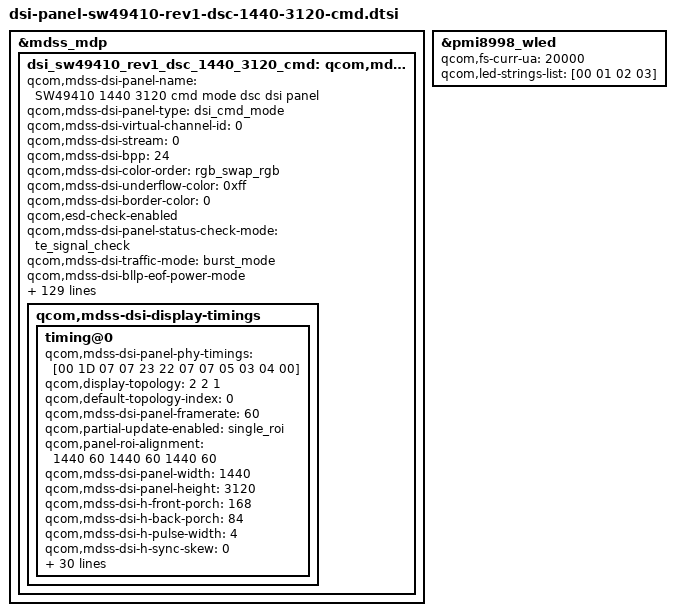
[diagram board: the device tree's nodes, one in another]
/* Copyright (c) 2014, Code Aurora Forum. All rights reserved.
 *
 * This program is free software; you can redistribute it and/or modify
 * it under the terms of the GNU General Public License version 2 and
 * only version 2 as published by the Free Software Foundation.
 *
 * This program is distributed in the hope that it will be useful,
 * but WITHOUT ANY WARRANTY; without even the implied warranty of
 * MERCHANTABILITY or FITNESS FOR A PARTICULAR PURPOSE.  See the
 * GNU General Public License for more details.
 */

&mdss_mdp {
	dsi_sw49410_rev1_dsc_1440_3120_cmd: qcom,mdss_dsi_sw49410_rev1_dsc_1440_3120_cmd {
		qcom,mdss-dsi-panel-name = "SW49410 1440 3120 cmd mode dsc dsi panel";
		qcom,mdss-dsi-panel-type = "dsi_cmd_mode";
		qcom,mdss-dsi-virtual-channel-id = <0>;
		qcom,mdss-dsi-stream = <0>;
		qcom,mdss-dsi-bpp = <24>;
		qcom,mdss-dsi-color-order = "rgb_swap_rgb";
		qcom,mdss-dsi-underflow-color = <0xff>;
		qcom,mdss-dsi-border-color = <0>;
		qcom,esd-check-enabled;
		qcom,mdss-dsi-panel-status-check-mode = "te_signal_check";
		qcom,mdss-dsi-traffic-mode = "burst_mode";
		qcom,mdss-dsi-bllp-eof-power-mode;
		qcom,mdss-dsi-bllp-power-mode;
		qcom,mdss-dsi-lane-0-state;
		qcom,mdss-dsi-lane-1-state;
		qcom,mdss-dsi-lane-2-state;
		qcom,mdss-dsi-lane-3-state;
		qcom,mdss-dsi-reset-sequence = <1 10>, <0 10>, <1 10>;
		qcom,mdss-dsi-bl-max-level = <4095>;
		qcom,adjust-timer-wakeup-ms = <1>;
		qcom,mdss-dsi-dma-trigger = "trigger_sw";
		qcom,mdss-dsi-mdp-trigger = "none";
		qcom,mdss-dsi-te-pin-select = <1>;
		qcom,mdss-dsi-wr-mem-start = <0x2c>;
		qcom,mdss-dsi-wr-mem-continue = <0x3c>;
		qcom,mdss-dsi-te-dcs-command = <1>;
		qcom,mdss-dsi-te-check-enable;
		qcom,mdss-dsi-te-using-te-pin;
		qcom,ulps-enabled;
		qcom,suspend-ulps-enabled;
		qcom,mdss-dsi-lp11-init;
		qcom,mdss-dsi-tx-eot-append;
		qcom,mdss-mdp-transfer-time-us = <15200>;

		lge,use-mplus;
		lge,use-hl-mode;
		lge,use-u2-fsc;
		lge,fsc-curr-ua-u3 = <20000>;
		lge,fsc-curr-ua-u2 = <2500>;
		lge,incell-panel;
		lge,use-color-manager;
		lge,drs-mngr-enabled;
		lge,use-ambient;
		lge,aod-interface-data = <0x144>; /* QHD = 1, FHD = 4, HD = 4 */
		lge,use-panel-reset-low-before-lp11;
		lge,use-extra-recovery-cmd;

		qcom,mdss-dsi-panel-hdr-enabled;
		qcom,mdss-dsi-panel-hdr-color-primaries = <14649 15851 33084 15473 13806 31961 7476 2719>;
		qcom,mdss-dsi-panel-peak-brightness = <5000000>;	/* max. 500nits */
		qcom,mdss-dsi-panel-blackness-level = <3022>;

		lge,blmap = <
			0
			16 16 16 16 16 16 16 16 16 16 16 16 16 16 17 17 17 17 18 18
			18 18 19 20 21 22 23 24 25 26 27 28 29 30 31 32 34 35 37 38
			40 42 43 45 46 48 49 51 53 56 59 63 66 70 73 76 80 83 87 90
			93 96 99 103 106 109 112 115 119 122 125 128 132 136 141 146 151 155 160 165
			170 174 179 184 189 194 199 205 210 215 221 226 232 237 242 248 253 259 266 274
			281 289 296 304 311 319 326 334 342 349 356 363 370 378 385 392 399 407 414 421
			428 436 445 454 464 473 482 492 501 510 520 529 538 548 558 569 580 591 602 612
			623 634 645 655 667 677 687 697 707 717 727 738 748 758 768 778 788 799 811 823
			835 847 859 872 880 896 908 920 932 945 957 969 981 994 1006 1018 1031 1043 1055 1068
			1080 1092 1105 1119 1134 1149 1164 1178 1193 1208 1223 1237 1252 1267 1282 1296 1311 1326 1341 1356
			1371 1385 1400 1415 1430 1445 1460 1475 1493 1512 1530 1549 1568 1586 1605 1624 1642 1661 1680 1697
			1714 1732 1749 1766 1784 1801 1819 1836 1853 1871 1888 1906 1926 1946 1966 1986 2006 2026 2046 2066
			2086 2106 2126 2147 2170 2194 2218 2242 2266 2290 2314 2338 2362 2386 2410
		>;

		lge,blmap-psm = <
			0
			16 16 16 16 16 16 16 16 16 16 16 16 16 17 17 17 17 17 17 18
			18 18 18 19 20 21 21 22 23 24 25 26 26 27 28 29 31 32 33 35
			36 37 38 40 41 42 44 45 47 49 52 54 56 58 60 62 65 67 69 71
			74 77 80 82 85 88 91 94 97 99 102 105 109 113 116 120 124 128 131 135
			139 143 146 150 154 158 163 167 171 175 180 184 188 192 197 201 205 210 216 221
			227 232 238 243 248 254 259 265 270 276 283 289 295 301 308 314 320 326 333 339
			345 352 359 366 373 380 388 395 402 409 416 423 430 437 444 451 459 466 473 480
			487 494 502 509 516 523 532 540 549 558 566 575 584 592 601 610 618 627 636 646
			655 665 674 684 693 702 712 721 731 740 751 761 772 782 793 804 814 825 835 846
			856 867 878 888 899 909 920 931 941 952 963 973 984 994 1005 1018 1030 1043 1055 1068
			1080 1093 1105 1118 1130 1143 1155 1168 1182 1195 1209 1222 1236 1249 1262 1276 1289 1303 1316 1331
			1345 1360 1374 1389 1404 1418 1433 1447 1462 1476 1491 1506 1520 1535 1549 1564 1578 1593 1607 1622
			1636 1651 1665 1680 1699 1717 1736 1755 1773 1792 1810 1829 1848 1866 1885
		>;

		lge,blmap-gal = <
			0
			16 16 16 16 16 16 16 16 16 16 16 17 17 17 18 18 18 18 19 19
			19 20 20 21 22 23 24 25 26 27 28 29 30 31 32 34 36 38 40 42
			44 45 47 49 51 53 55 57 60 63 66 69 72 75 78 81 84 87 90 93
			97 101 105 109 113 118 122 126 130 134 138 142 147 152 157 162 167 173 178 183
			188 193 198 203 209 215 221 227 233 239 244 250 256 262 268 274 280 287 295 302
			309 317 324 331 339 346 353 361 368 377 386 394 403 412 421 429 438 447 456 464
			473 482 492 501 511 520 530 539 548 558 567 577 586 596 606 616 626 636 646 655
			665 675 685 695 705 715 727 739 751 763 775 788 800 812 824 836 848 860 873 887
			900 913 926 940 953 966 979 993 1006 1019 1034 1048 1063 1077 1092 1107 1121 1136 1150 1165
			1179 1194 1209 1223 1238 1253 1267 1282 1297 1312 1326 1341 1356 1370 1385 1403 1420 1438 1456 1473
			1491 1509 1526 1544 1562 1579 1597 1616 1635 1654 1673 1692 1711 1730 1749 1768 1787 1806 1825 1846
			1866 1887 1908 1928 1949 1970 1990 2011 2032 2052 2073 2093 2114 2134 2155 2175 2195 2216 2236 2256
			2277 2297 2318 2338 2365 2391 2418 2444 2471 2497 2524 2550 2577 2603 2630
		>;

		lge,blmap-hqc = <
			0
			16 16 16 16 16 16 16 16 16 16 16 16 17 17 17 17 18 18 18 18
			19 19 19 20 21 22 23 24 26 27 28 29 30 31 32 34 36 37 39 41
			43 44 46 48 50 51 53 55 58 61 64 67 70 73 75 78 81 84 87 90
			94 98 102 106 110 114 118 122 126 130 134 138 143 148 152 157 162 167 171
			176 181 186 190 195 201 207 212 218 224 230 235 241 247 253 258 264 270 277 284
			291 298 305 313 320 327 334 341 348 355 363 371 380 388 396 404 412 420 429 437
			445 453 462 472 481 490 500 509 518 528 537 546 556 565 575 584 594 603 613 623
			632 642 652 661 671 680 690 702 714 726 738 750 762 773 785 797 809 821 833 846
			859 872 885 898 912 925 938 951 964 977 990 1005 1020 1035 1050 1065 1080 1095 1110 1125
			1140 1155 1170 1185 1199 1214 1228 1243 1258 1272 1287 1302 1316 1331 1345 1360 1378 1396 1414 1432
			1450 1468 1486 1504 1522 1540 1558 1576 1595 1615 1634 1653 1673 1692 1711 1731 1750 1769 1789 1808
			1829 1850 1871 1892 1913 1934 1955 1976 1997 2018 2039 2060 2081 2103 2124 2146 2167 2188 2210 2231
			2252 2274 2295 2317 2338 2365 2391 2418 2444 2471 2497 2524 2550 2577 2603 2630
		>;

		lge,blmap-max = <
			0
			2630 2635 2640 2645 2650 2654 2659 2664 2669 2674 2679 2684 2689 2693 2698 2703 2708 2713 2718 2723
			2728 2733 2737 2742 2747 2752 2757 2762 2767 2772 2776 2781 2786 2791 2796 2801 2806 2811 2816 2820
			2825 2830 2835 2840 2845 2850 2855 2859 2864 2869 2874 2879 2884 2889 2894 2899 2903 2908 2913 2918
			2923 2928 2933 2938 2942 2947 2952 2957 2962 2967 2972 2977 2981 2986 2991 2996 3001 3006 3011 3016
			3021 3025 3030 3035 3040 3045 3050 3055 3060 3064 3069 3074 3079 3084 3089 3094 3099 3104 3108 3113
			3118 3123 3128 3133 3138 3143 3147 3152 3157 3162 3167 3172 3177 3182 3187 3191 3196 3201 3206 3211
			3216 3221 3226 3230 3235 3240 3245 3250 3255 3260 3265 3270 3274 3279 3284 3289 3294 3299 3304 3309
			3313 3318 3323 3328 3333 3338 3343 3348 3353 3357 3362 3367 3372 3377 3382 3387 3392 3396 3401 3406
			3411 3416 3421 3426 3431 3436 3440 3445 3450 3455 3460 3465 3470 3475 3479 3484 3489 3494 3499 3504
			3509 3514 3519 3523 3528 3533 3538 3543 3548 3553 3558 3562 3567 3572 3577 3582 3587 3592 3597 3601
			3606 3611 3616 3621 3626 3631 3636 3641 3645 3650 3655 3660 3665 3670 3675 3680 3684 3689 3694 3699
			3704 3709 3714 3719 3724 3728 3733 3738 3743 3748 3753 3758 3763 3767 3772 3777 3782 3787 3792 3797
			3802 3807 3811 3816 3821 3826 3831 3836 3841 3846 3850 3855 3860 3865 3870
		>;

		lge,blmap-hl = <
			0
			2410 2435 2460 2485 2510 2535 2560 2585 2610 2630
		>;

		lge,blmap-psm-hl = <
			0
			1885 1888 1891 1894 1897 1900 1903 1906 1908 1911 1914 1917 1920 1923 1926 1929 1932 1935 1938 1941
			1944 1947 1950 1952 1955 1958 1961 1964 1967 1970 1973 1976 1979 1982 1985 1988 1991 1994 1996 1999
			2002 2005 2008 2011 2014 2017 2020 2023 2026 2029 2032 2035 2038 2040 2043 2046 2049 2052 2055 2058
			2061 2064 2067 2070 2073 2076 2079 2082 2084 2087 2090 2093 2096 2099 2102 2105 2108 2111 2114 2117
			2120 2123 2126 2128 2131 2134 2137 2140 2143 2146 2149 2152 2155 2158 2161 2164 2167 2170 2172 2175
			2178 2181 2184 2187 2190 2193 2196 2199 2202 2205 2208 2211 2214 2216 2219 2222 2225 2228 2231 2234
			2237 2240 2243 2246 2249 2252 2255 2258 2260 2263 2266 2269 2272 2275 2278 2281 2284 2287 2290 2293
			2296 2299 2301 2304 2307 2310 2313 2316 2319 2322 2325 2328 2331 2334 2337 2340 2343 2345 2348 2351
			2354 2357 2360 2363 2366 2369 2372 2375 2378 2381 2384 2387 2389 2392 2395 2398 2401 2404 2407 2410
			2413 2416 2419 2422 2425 2428 2431 2433 2436 2439 2442 2445 2448 2451 2454 2457 2460 2463 2466 2469
			2472 2475 2477 2480 2483 2486 2489 2492 2495 2498 2501 2504 2507 2510 2513 2516 2519 2521 2524 2527
			2530 2533 2536 2539 2542 2545 2548 2551 2554 2557 2560 2563 2565 2568 2571 2574 2577 2580 2583 2586
			2589 2592 2595 2598 2601 2604 2607 2609 2612 2615 2618 2621 2624 2627 2630
		>;

		lge,blmap-gal-hl = <
			0
			2630 2630 2630 2630 2630 2630 2630 2630 2630 2630
		>;

		lge,blmap-hqc-hl = <
			0
			2630 2630 2630 2630 2630 2630 2630 2630 2630 2630
		>;

		lge,blmap-max-hl = <
			0
			3870 3870 3870 3870 3870 3870 3870 3870 3870 3870
		>;

		lge,blmap-hbm-hd = <
			0
			16 26 37 47 57 67 78 88 98 109 119 129 139 150 160 170 181 191 201 212
			222 232 242 253 263 273 284 294 304 314 325 335 345 356 366 376 386 397 407 417
			428 438 448 459 469 479 489 500 510 520 531 541 551 561 572 582 592 603 613 623
			633 644 654 664 675 685 695 706 716 726 736 747 757 767 778 788 798 808 819 829
			839 850 860 870 880 891 901 911 922 932 942 953 963 973 983 994 1004 1014 1025 1035
			1045 1055 1066 1076 1086 1097 1107 1117 1127 1138 1148 1158 1169 1179 1189 1200 1210 1220 1230 1241
			1251 1261 1272 1282 1292 1302 1313 1323 1333 1344 1354 1364 1374 1385 1395 1405 1416 1426 1436 1446
			1457 1467 1477 1488 1498 1508 1519 1529 1539 1549 1560 1570 1580 1591 1601 1611 1621 1632 1642 1652
			1663 1673 1683 1693 1704 1714 1724 1735 1745 1755 1766 1776 1786 1796 1807 1817 1827 1838 1848 1858
			1868 1879 1889 1899 1910 1920 1930 1940 1951 1961 1971 1982 1992 2002 2013 2023 2033 2043 2054 2064
			2074 2085 2095 2105 2115 2126 2136 2146 2157 2167 2177 2187 2198 2208 2218 2229 2239 2249 2260 2270
			2280 2290 2301 2311 2321 2332 2342 2352 2362 2373 2383 2393 2404 2414 2424 2434 2445 2455 2465 2476
			2486 2496 2507 2517 2527 2537 2548 2558 2568 2579 2589 2599 2609 2620 2630
		>;

		lge,blmap-ex = <
			0
			16 16 16 16 16 16 16 16 16 18 20 22 25 27 29 31 33 35 37 40
			42 44 46 48 50 53 55 57 59 61 63 65 68 70 72 74 81 87 94 100
			107 113 120 127 133 140 146 153 159 166 172 179 186 192 199 205 212 218 225 232
			238 245 251 258 264 271 277 284 291 297 304 310 317 323 330 342 354 366 378 390
			402 414 426 438 450 462 474 486 498 510 522 534 546 558 570 582 594 594 594 594
			594 594 594 594 594 594 594 594 594 594 594 594 594 594 594 615 637 658 679 701
			722 744 765 786 808 829 850 872 893 915 936 957 979 1000 1039 1078 1117 1156 1195 1234
			1248 1262 1276 1290 1304 1318 1332 1346 1360 1374 1388 1402 1416 1430 1444 1458 1472 1486 1500
		>;

		qcom,mdss-pan-physical-width-dimension = <65>;
		qcom,mdss-pan-physical-height-dimension = <140>;

		qcom,mdss-dsi-t-clk-post = <0x0D>;
		qcom,mdss-dsi-t-clk-pre = <0x2D>;

		lge,mdss-dsi-ddic-mplus-command = [39 01 00 00 00 00 05 D3 12 01 00 00];
		lge,mdss-dsi-ddic-mplus-command-state = "dsi_hs_mode";

		lge,mplus-mode-set1-command = [39 01 00 00 00 00 96 D4 DC 5F 9C BE 39 39 39 47 48 48 48 3A 00 03 6D 80 00 00 8C 66 00 00 8C 66 00 00 8C 66 00 0A 48 80 00 0A 48 80 00 0A 48 80 00 0A 48 80 20 0A 14 0A 18 00 1C CC 23 9E 23 9E 01 01 01 01 04 04 04 04 01 00 02 80 00 10 00 10 00 10 13 9E 13 9E 13 9E 13 9E 05 05 05 05 05 05 05 05 23 9E FF FF 13 33 18 00 16 66 10 00 FF 01 00 02 00 03 00 04 00 05 00 06 00 07 00 08 00 09 00 0A 00 0B 00 0C 00 0D 00 0E 00 0F 00 1B 25 DC 18 00 20 00 1C E1 00 FF E0 C8 C8 41 8F];
		lge,mplus-mode-set1-command-state = "dsi_hs_mode";

		lge,mplus-mode-set2-command = [39 01 00 00 00 00 96 D4 DC 5F 9C BE 39 39 39 47 48 48 48 3A 00 03 6D 80 00 00 8C 66 00 00 8C 66 00 00 8C 66 00 0A 48 80 00 0A 48 80 00 0A 48 80 00 0A 48 80 20 0A 14 0A 18 00 1C CC 23 9E 23 9E 01 01 01 01 04 04 04 04 01 00 02 80 00 10 00 10 00 10 13 9E 13 9E 13 9E 13 9E 05 05 05 05 05 05 05 05 23 9E FF FF 13 33 18 00 16 66 10 00 FF 01 00 02 00 03 00 04 00 05 00 06 00 07 00 08 00 09 00 0A 00 0B 00 0C 00 0D 00 0E 00 0F 00 1B 25 DC 18 00 20 00 1C E1 00 FF E0 C8 C8 41 8F];
		lge,mplus-mode-set2-command-state = "dsi_hs_mode";

		lge,mplus-mode-set3-command = [39 01 00 00 00 00 96 D4 DC 5F 9C A6 39 39 39 47 48 48 48 3A 00 22 47 00 00 2F FD 00 00 22 47 00 00 0D B6 00 00 89 1C 00 00 2F FD 00 00 22 47 00 00 0D B6 00 20 00 00 00 18 00 23 9E 23 9E 23 9E 06 06 06 06 05 05 05 05 01 00 02 80 00 C8 01 80 00 30 13 9E 13 9E 13 9E 13 9E 10 10 10 10 10 10 10 10 23 9E FF FF 18 00 18 00 16 66 10 00 FF 01 00 02 00 03 00 04 00 05 00 06 00 07 00 08 00 09 00 0A 00 0B 00 0C 00 0D 00 0E 00 0F 00 1B 25 DC 18 00 20 00 1C E1 00 FF E0 C8 C8 41 8F];
		lge,mplus-mode-set3-command-state = "dsi_hs_mode";

		lge,digital-gamma-cmds-dummy = [
			39 01 00 00 00 00 11 F6 40 40 40 40 40 40 40 40 00 00 00 00 00 00 00 00
			39 01 00 00 00 00 11 F7 40 40 40 40 40 40 40 40 00 00 00 00 00 00 00 00
			39 01 00 00 00 00 11 F8 40 40 40 40 40 40 40 40 00 00 00 00 00 00 00 00
			39 01 00 00 00 00 02 F5 00
		];
		lge,digital-gamma-cmds-dummy-command = "dsi_hs_mode";

		lge,selective-color-cmds-dummy-command = [
			39 01 00 00 00 00 06 F3 00 01 00 0D 00
			39 01 00 00 00 00 0E F4 00 00 40 83 C5 00 01 00 00 00 00 00 00
		];
		lge,selective-color-cmds-dummy-command-state = "dsi_hs_mode";

		lge,mdss-dsi-ie-command = [
			15 01 00 00 00 00 02 55 81
			39 01 00 00 00 00 0E FC 13 70 D0 26 30 7C 02 FF 12 22 22 10 00
		];
		lge,mdss-dsi-ie-command-state = "dsi_hs_mode";

		lge,mdss-dsi-aod-area-command = [
			/* Partial Area */
			39 01 00 00 00 00 05 30 00 00 03 1F
			/* U2 Control */
			39 01 00 00 00 00 12 CD 09 86 02 80 00 00 00 00 00 00 00 00 0C 12 00 00 00
		];
		lge,mdss-dsi-aod-area-command-state = "dsi_lp_mode";

		lge,mdss-dsi-lp2-command = [
			/*Black Frame Setting*/
			39 01 00 00 00 00 03 BD 01 05
			/* U2 Corner Down */
			39 01 00 00 00 00 03 BF 4F 00
			/* Partial Mode ON  + min 55ms*/
			05 01 00 00 37 00 01 12
		];
		lge,mdss-dsi-lp2-command-state = "dsi_lp_mode";

		lge,mdss-dsi-nolp-command = [
			/*Black Frame Setting*/
			39 01 00 00 00 00 03 BD 01 05
			/* U2 Corner Down */
			39 01 00 00 00 00 03 BF 4F 02
			/* Mormal Mode ON + min 40ms*/
			05 01 00 00 28 00 01 13
		];
		lge,mdss-dsi-nolp-command-state = "dsi_lp_mode";

		lge,mdss-dsi-sharpness-command = [39 01 00 00 00 00 06 F3 00 01 00 0D 00];
		lge,mdss-dsi-sharpness-command-state = "dsi_hs_mode";

		lge,mdss-dsi-bist-on-command = [
			39 01 00 00 21 00 07 EE 01 00 00 00 00 00
		];
		lge,mdss-dsi-bist-off-command = [
			39 01 00 00 21 00 07 EE 00 00 00 00 00 00
		];

		lge,use-high-temp-tune;
		lge,mdss-dsi-high-temp-tune0-command = [
			39 01 00 00 00 00 13 C3 92 11 09 09 11 CC 02 02 A4 A4 02 A2 38 28 14 40 38 C0
			15 01 00 00 00 00 02 26 01
		];
		lge,mdss-dsi-high-temp-tune0-command-state = "dsi_hs_mode";
		lge,mdss-dsi-high-temp-tune1-command = [
			39 01 00 00 00 00 13 C3 92 11 09 09 11 CC 02 02 A4 A4 02 A2 38 28 14 3E 36 C0
			15 01 00 00 00 00 02 26 01
		];
		lge,mdss-dsi-high-temp-tune1-command-state = "dsi_hs_mode";
		lge,mdss-dsi-high-temp-tune2-command = [
			39 01 00 00 00 00 13 C3 92 11 09 09 11 CC 02 02 A4 A4 02 A2 38 28 14 3C 34 C0
			15 01 00 00 00 00 02 26 02
		];
		lge,mdss-dsi-high-temp-tune2-command-state = "dsi_hs_mode";
		lge,mdss-dsi-high-temp-tune3-command = [
			39 01 00 00 00 00 13 C3 92 11 09 09 11 CC 02 02 A4 A4 02 A2 38 28 14 3A 32 C0
			15 01 00 00 00 00 02 26 02
		];
		lge,mdss-dsi-high-temp-tune3-command-state = "dsi_hs_mode";
		lge,mdss-dsi-high-temp-tune4-command = [
			39 01 00 00 00 00 13 C3 92 11 09 09 11 CC 02 02 A4 A4 02 A2 38 28 14 37 30 C0
			15 01 00 00 00 00 02 26 04
		];
		lge,mdss-dsi-high-temp-tune4-command-state = "dsi_hs_mode";

		qcom,mdss-dsi-display-timings {
			timing@0{
				qcom,mdss-dsi-panel-phy-timings = [00 1D 07 07 23 22 07 07 05 03 04 00];
				qcom,display-topology = <2 2 1>;
				qcom,default-topology-index = <0>;
				qcom,mdss-dsi-panel-framerate = <60>;
				qcom,partial-update-enabled = "single_roi";
				qcom,panel-roi-alignment = <1440 60 1440 60 1440 60>;
				qcom,mdss-dsi-panel-width = <1440>;
				qcom,mdss-dsi-panel-height = <3120>;
				qcom,mdss-dsi-h-front-porch = <168>;
				qcom,mdss-dsi-h-back-porch = <84>;
				qcom,mdss-dsi-h-pulse-width = <4>;
				qcom,mdss-dsi-h-sync-skew = <0>;
				qcom,mdss-dsi-v-back-porch = <18>;
				qcom,mdss-dsi-v-front-porch = <2>;
				qcom,mdss-dsi-v-pulse-width = <18>;
				qcom,mdss-dsi-h-left-border = <0>;
				qcom,mdss-dsi-h-right-border = <0>;
				qcom,mdss-dsi-v-top-border = <0>;
				qcom,mdss-dsi-v-bottom-border = <0>;
				qcom,mdss-dsi-h-sync-pulse = <0>;

				qcom,mdss-dsi-on-command = [
					/* TE On */
					15 01 00 00 00 00 02 35 00
					/* Page Address Set */
					39 01 00 00 00 00 05 2B 00 00 0C 2F
					/* BLU Control */
					15 01 00 00 00 00 02 51 FF
					15 01 00 00 00 00 02 53 2C
					15 01 00 00 00 00 02 5E 00
					15 01 00 00 00 00 02 55 81
					/*Manufacturer protection*/
					15 01 00 00 00 00 02 B0 AC
					/*Source Control*/
					39 01 00 00 00 00 09 B3 04 04 28 08 5A 12 23 02
					/*Gate & Mux Control*/
					39 01 00 00 00 00 20 B4 11 04 02 02 02 02 02 01 01 01 01 01 01 D0 E4 E4 E4 93 4E 39 0A 10 18 25 24 00 00 00 00 00 00
					/*Sync Setup*/
					39 01 00 00 00 00 09 B5 2E 0F 10 C0 00 10 C0 00
					/*Panel Setting*/
					39 01 00 00 00 00 06 B6 03 05 0B B3 30
					/*Touch Timing Control*/
					39 01 00 00 00 00 20 B8 57 02 90 40 5D D0 05 00 00 18 22 04 01 02 90 40 4C C0 04 00 00 18 22 04 01 08 00 3A 86 83 00
					/*Touch Source Setting*/
					39 01 00 00 00 00 06 B9 64 64 2A 3F EE
					/*DSC Configuration*/
					39 01 00 00 00 00 0C BA 3D 1F 01 FF 01 3C 1F 01 FF 01 00
					/*Low Rate Refresh Setting*/
					39 01 00 00 00 00 05 BC 00 00 00 90
					/*Black Frame Setting*/
					39 01 00 00 00 00 03 BD 00 00
					/* U2 Corner Down */
					39 01 00 00 00 00 03 BF 4F 02
					/*Internal Oscillator Setting*/
					39 01 00 00 00 00 0B C0 00 04 18 07 11 11 3C 00 0A 0A
					/*Power Control1*/
					39 01 00 00 00 00 07 C1 01 00 F0 C2 CF 0C
					/*Power Control2*/
					39 01 00 00 00 00 09 C2 CC 44 44 20 22 26 21 00
					/*Power Control3*/
					39 01 00 00 00 00 13 C3 92 11 09 09 11 CC 02 02 A4 A4 02 A2 38 28 14 40 38 C0
					/*Vcom Setting*/
					39 01 00 00 00 00 03 C4 26 00
					/*Power Sequence Option Configuration*/
					39 01 00 00 00 00 06 C9 05 5D 03 04 00
					/*Abrupt Power Off Control*/
					39 01 00 00 00 00 03 CA 9B 10
					/*LFD Control*/
					39 01 00 00 00 00 06 CB F3 90 3D 30 CC
					/*Tail TFT Setting*/
					39 01 00 00 00 00 06 CC 00 40 50 90 41
					/*U2 Option*/
					39 01 00 00 00 00 03 CE 00 00
					/*Gamma*/
					39 01 00 00 00 00 A9 D0 12 05 20 1B 2C 28 3F 3D 4F 4F 66 66 6E 6E 76 76 80 80 88 88 95 95 3F 3F A2 A2 94 94 8B 8B 81 81 75 75 66 66 47 47 2D 2D 00 01 12 05 20 1B 2C 28 3F 3D 4F 4F 66 66 6E 6E 76 76 80 80 88 88 95 95 3F 3F A2 A2 94 94 8B 8B 81 81 75 75 66 66 47 47 2D 2D 00 01 12 05 20 1B 2C 28 3F 3D 4F 4F 66 66 6E 6E 76 76 80 80 88 88 95 95 3F 3F A2 A2 94 94 8B 8B 81 81 75 75 66 66 47 47 2D 2D 00 01 12 05 20 1B 2C 28 3F 3D 4F 4F 66 66 6E 6E 76 76 80 80 88 88 94 94 3F 3F A4 A4 95 95 8B 8B 81 81 75 75 66 66 47 47 2D 2D 00 01
					39 01 00 00 00 00 A9 D1 12 05 20 1B 2E 29 41 3F 52 52 6A 6A 72 72 7a 7A 84 84 8C 8C 9A 9A 3F 3F 9B 9B 8D 8D 84 84 7A 7A 6E 6E 5F 5F 41 41 2A 2A 00 01 12 05 20 1B 2E 29 41 3f 52 52 6A 6A 72 72 7A 7A 84 84 8C 8C 9A 9A 3F 3F 9B 9B 8D 8D 84 84 7A 7A 6E 6E 5F 5F 41 41 2A 2A 00 01 12 05 20 1B 2E 29 41 3f 52 52 6A 6A 72 72 7A 7A 84 84 8C 8C 9A 9A 3F 3F 9B 9B 8D 8D 84 84 7A 7A 6E 6E 5F 5F 41 41 2A 2A 00 01 12 05 20 1B 2E 29 41 3f 52 52 6A 6A 72 72 7A 7A 84 84 8C 8C 9A 9A 3F 3F 9B 9B 8D 8D 84 84 7A 7A 6E 6E 5F 5F 41 41 2A 2A 00 01
					39 01 00 00 00 00 A9 D2 12 05 20 1B 2F 2A 43 41 55 55 6E 6E 76 76 7E 7E 88 88 90 90 9F 9F 3F 3F 95 95 86 86 7D 7D 74 74 68 68 59 59 3C 3C 26 26 00 01 12 05 20 1B 2F 2A 43 41 55 55 6E 6E 76 76 7E 7E 88 88 90 90 9F 9F 3F 3F 95 95 86 86 7D 7D 74 74 68 68 59 59 3C 3C 26 26 00 01 12 05 20 1B 2F 2A 43 41 55 55 6E 6E 76 76 7E 7E 88 88 90 90 9F 9F 3F 3F 95 95 86 86 7D 7D 74 74 68 68 59 59 3C 3C 26 26 00 01 12 05 20 1B 2F 2A 43 41 55 55 6E 6E 76 76 7E 7E 88 88 90 90 9F 9F 3F 3F 95 95 86 86 7D 7D 74 74 68 68 59 59 3C 3C 26 26 00 01
					/* MPLUS Control */
					39 01 00 00 00 00 05 D3 12 01 00 00
					/*Mplus Setting*/
					39 01 00 00 00 00 96 D4 DC 5F 9C BE 39 39 39 47 48 48 48 3A 00 03 6D 80 00 00 8C 66 00 00 8C 66 00 00 8C 66 00 0A 48 80 00 0A 48 80 00 0A 48 80 00 0A 48 80 20 0A 14 0A 18 00 1C CC 23 9E 23 9E 01 01 01 01 04 04 04 04 01 00 02 80 00 10 00 10 00 10 13 9E 13 9E 13 9E 13 9E 05 05 05 05 05 05 05 05 23 9E FF FF 13 33 18 00 16 66 10 00 FF 01 00 02 00 03 00 04 00 05 00 06 00 07 00 08 00 09 00 0A 00 0B 00 0C 00 0D 00 0E 00 0F 00 1B 25 DC 18 00 20 00 1C E1 00 FF E0 C8 C8 41 8F
					/*Notch Up Gradation*/
					39 01 00 00 00 00 21 AD 01 02 03 04 05 06 06 06 06 06 06 06 06 06 06 06 20 40 60 90 C0 F0 FF FF FF FF FF FF FF FF FF FF
					/*Notch Down Gradation*/
					39 01 00 00 00 00 21 AE 01 02 03 04 05 06 06 06 06 06 06 06 06 06 06 06 20 40 60 90 C0 F0 FF FF FF FF FF FF FF FF FF FF
					/*GIP Setting*/
					39 01 00 00 00 00 1B E5 0B 0A 0C 00 02 04 06 08 0F 1B 02 1A 1A 0B 0A 0C 01 03 05 07 09 10 1B 03 1A 1A
					/*Mux Setting*/
					39 01 00 00 00 00 11 E6 11 12 13 14 15 16 17 18 11 12 13 14 15 16 17 18
					/*Test1*/
					39 01 00 00 00 00 07 ED 21 49 00 00 00 00
					/*BLU Control*/
					15 01 00 00 00 00 02 55 81
					/*Sharpness*/
					39 01 00 00 00 00 06 F3 00 01 00 0D 00
					39 01 00 00 00 00 0E F4 00 00 40 83 C5 00 01 00 00 00 00 00 00
					39 01 00 00 00 00 18 FB 20 40 60 80 a0 c0 e0 13 18 18 18 16 0D 0D 00 C7 CF D8 E1 EA F3 F9 FF
					/*Gamma Correction*/
					39 01 00 00 00 00 02 F5 00
					39 01 00 00 00 00 11 F6 40 40 40 40 40 40 40 40 00 00 00 00 00 00 00 00
					39 01 00 00 00 00 11 F7 40 40 40 40 40 40 40 40 00 00 00 00 00 00 00 00
					39 01 00 00 00 00 11 F8 40 40 40 40 40 40 40 40 00 00 00 00 00 00 00 00
					/*BLU PWM Control*/
					39 01 00 00 00 00 0E FC 13 70 D0 26 30 7C 02 FF 12 22 22 10 00
					/* Normal Display mode on */
					05 01 00 00 00 00 01 13
					/* Sleep Out + min 120ms */
					05 01 00 00 80 00 01 11
					/*Black Frame Setting*/
					39 01 00 00 00 00 03 BD 01 05
					05 01 00 00 05 00 01 29
				];

				qcom,mdss-dsi-on-command-with-apo = [
					/* TE On */
					15 01 00 00 00 00 02 35 00
					/* Page Address Set */
					39 01 00 00 00 00 05 2B 00 00 0C 2F
					/* BLU Control */
					15 01 00 00 00 00 02 51 FF
					15 01 00 00 00 00 02 53 2C
					15 01 00 00 00 00 02 5E 00
					15 01 00 00 00 00 02 55 81
					/*Manufacturer protection*/
					15 01 00 00 00 00 02 B0 AC
					/*Source Control*/
					39 01 00 00 00 00 09 B3 04 04 28 08 5A 12 23 02
					/*Gate & Mux Control*/
					39 01 00 00 00 00 20 B4 11 04 02 02 02 02 02 01 01 01 01 01 01 D0 E4 E4 E4 93 4E 39 0A 10 18 25 24 00 00 00 00 00 00
					/*Sync Setup*/
					39 01 00 00 00 00 09 B5 2E 0F 10 C0 00 10 C0 00
					/*Panel Setting*/
					39 01 00 00 00 00 06 B6 03 05 0B B3 30
					/*Touch Timing Control*/
					39 01 00 00 00 00 20 B8 57 02 90 40 5D D0 05 00 00 18 22 04 01 02 90 40 4C C0 04 00 00 18 22 04 01 08 00 3A 86 83 00
					/*Touch Source Setting*/
					39 01 00 00 00 00 06 B9 64 64 2A 3F EE
					/*DSC Configuration*/
					39 01 00 00 00 00 0C BA 3D 1F 01 FF 01 3C 1F 01 FF 01 00
					/*Low Rate Refresh Setting*/
					39 01 00 00 00 00 05 BC 00 00 00 90
					/*Black Frame Setting*/
					39 01 00 00 00 00 03 BD 00 00
					/* U2 Corner Down */
					39 01 00 00 00 00 03 BF 4F 02
					/*Internal Oscillator Setting*/
					39 01 00 00 00 00 0B C0 00 04 18 07 11 11 3C 00 0A 0A
					/*Power Control1*/
					39 01 00 00 00 00 07 C1 01 00 F0 C2 CF 0C
					/*Power Control2*/
					39 01 00 00 00 00 09 C2 CC 44 44 20 22 26 21 00
					/*Power Control3*/
					39 01 00 00 00 00 13 C3 92 11 09 09 11 CC 02 02 A4 A4 02 A2 38 28 14 40 38 C0
					/*Vcom Setting*/
					39 01 00 00 00 00 03 C4 26 00
					/*Power Sequence Option Configuration - source & vcom GND*/
					39 01 00 00 00 00 06 C9 01 54 03 04 00
					/*Abrupt Power Off Control*/
					39 01 00 00 00 00 03 CA 9B 10
					/*LFD Control*/
					39 01 00 00 00 00 06 CB F3 90 3D 30 CC
					/*Tail TFT Setting*/
					39 01 00 00 00 00 06 CC 00 40 50 90 41
					/*U2 Option*/
					39 01 00 00 00 00 03 CE 00 00
					/*Gamma*/
					39 01 00 00 00 00 A9 D0 12 05 20 1B 2C 28 3F 3D 4F 4F 66 66 6E 6E 76 76 80 80 88 88 95 95 3F 3F A2 A2 94 94 8B 8B 81 81 75 75 66 66 47 47 2D 2D 00 01 12 05 20 1B 2C 28 3F 3D 4F 4F 66 66 6E 6E 76 76 80 80 88 88 95 95 3F 3F A2 A2 94 94 8B 8B 81 81 75 75 66 66 47 47 2D 2D 00 01 12 05 20 1B 2C 28 3F 3D 4F 4F 66 66 6E 6E 76 76 80 80 88 88 95 95 3F 3F A2 A2 94 94 8B 8B 81 81 75 75 66 66 47 47 2D 2D 00 01 12 05 20 1B 2C 28 3F 3D 4F 4F 66 66 6E 6E 76 76 80 80 88 88 94 94 3F 3F A4 A4 95 95 8B 8B 81 81 75 75 66 66 47 47 2D 2D 00 01
					39 01 00 00 00 00 A9 D1 12 05 20 1B 2E 29 41 3F 52 52 6A 6A 72 72 7a 7A 84 84 8C 8C 9A 9A 3F 3F 9B 9B 8D 8D 84 84 7A 7A 6E 6E 5F 5F 41 41 2A 2A 00 01 12 05 20 1B 2E 29 41 3f 52 52 6A 6A 72 72 7A 7A 84 84 8C 8C 9A 9A 3F 3F 9B 9B 8D 8D 84 84 7A 7A 6E 6E 5F 5F 41 41 2A 2A 00 01 12 05 20 1B 2E 29 41 3f 52 52 6A 6A 72 72 7A 7A 84 84 8C 8C 9A 9A 3F 3F 9B 9B 8D 8D 84 84 7A 7A 6E 6E 5F 5F 41 41 2A 2A 00 01 12 05 20 1B 2E 29 41 3f 52 52 6A 6A 72 72 7A 7A 84 84 8C 8C 9A 9A 3F 3F 9B 9B 8D 8D 84 84 7A 7A 6E 6E 5F 5F 41 41 2A 2A 00 01
					39 01 00 00 00 00 A9 D2 12 05 20 1B 2F 2A 43 41 55 55 6E 6E 76 76 7E 7E 88 88 90 90 9F 9F 3F 3F 95 95 86 86 7D 7D 74 74 68 68 59 59 3C 3C 26 26 00 01 12 05 20 1B 2F 2A 43 41 55 55 6E 6E 76 76 7E 7E 88 88 90 90 9F 9F 3F 3F 95 95 86 86 7D 7D 74 74 68 68 59 59 3C 3C 26 26 00 01 12 05 20 1B 2F 2A 43 41 55 55 6E 6E 76 76 7E 7E 88 88 90 90 9F 9F 3F 3F 95 95 86 86 7D 7D 74 74 68 68 59 59 3C 3C 26 26 00 01 12 05 20 1B 2F 2A 43 41 55 55 6E 6E 76 76 7E 7E 88 88 90 90 9F 9F 3F 3F 95 95 86 86 7D 7D 74 74 68 68 59 59 3C 3C 26 26 00 01
					/* MPLUS Control */
					39 01 00 00 00 00 05 D3 12 01 00 00
					/*Mplus Setting*/
					39 01 00 00 00 00 96 D4 DC 5F 9C BE 39 39 39 47 48 48 48 3A 00 03 6D 80 00 00 8C 66 00 00 8C 66 00 00 8C 66 00 0A 48 80 00 0A 48 80 00 0A 48 80 00 0A 48 80 20 0A 14 0A 18 00 1C CC 23 9E 23 9E 01 01 01 01 04 04 04 04 01 00 02 80 00 10 00 10 00 10 13 9E 13 9E 13 9E 13 9E 05 05 05 05 05 05 05 05 23 9E FF FF 13 33 18 00 16 66 10 00 FF 01 00 02 00 03 00 04 00 05 00 06 00 07 00 08 00 09 00 0A 00 0B 00 0C 00 0D 00 0E 00 0F 00 1B 25 DC 18 00 20 00 1C E1 00 FF E0 C8 C8 41 8F
					/*Notch Up Gradation*/
					39 01 00 00 00 00 21 AD 01 02 03 04 05 06 06 06 06 06 06 06 06 06 06 06 20 40 60 90 C0 F0 FF FF FF FF FF FF FF FF FF FF
					/*Notch Down Gradation*/
					39 01 00 00 00 00 21 AE 01 02 03 04 05 06 06 06 06 06 06 06 06 06 06 06 20 40 60 90 C0 F0 FF FF FF FF FF FF FF FF FF FF
					/*GIP Setting*/
					39 01 00 00 00 00 1B E5 0B 0A 0C 00 02 04 06 08 0F 1B 02 1A 1A 0B 0A 0C 01 03 05 07 09 10 1B 03 1A 1A
					/*Mux Setting*/
					39 01 00 00 00 00 11 E6 11 12 13 14 15 16 17 18 11 12 13 14 15 16 17 18
					/*Test1*/
					39 01 00 00 00 00 07 ED 21 49 00 00 00 00
					/*BLU Control*/
					15 01 00 00 00 00 02 55 81
					/*Sharpness*/
					39 01 00 00 00 00 06 F3 00 01 00 0D 00
					39 01 00 00 00 00 0E F4 00 00 40 83 C5 00 01 00 00 00 00 00 00
					39 01 00 00 00 00 18 FB 20 40 60 80 a0 c0 e0 13 18 18 18 16 0D 0D 00 C7 CF D8 E1 EA F3 F9 FF
					/*Gamma Correction*/
					39 01 00 00 00 00 02 F5 00
					39 01 00 00 00 00 11 F6 40 40 40 40 40 40 40 40 00 00 00 00 00 00 00 00
					39 01 00 00 00 00 11 F7 40 40 40 40 40 40 40 40 00 00 00 00 00 00 00 00
					39 01 00 00 00 00 11 F8 40 40 40 40 40 40 40 40 00 00 00 00 00 00 00 00
					/*BLU PWM Control*/
					39 01 00 00 00 00 0E FC 13 70 D0 26 30 7C 02 FF 12 22 22 10 00
					/* Normal Display mode on */
					05 01 00 00 00 00 01 13
					/* Sleep Out + min 120ms */
					05 01 00 00 80 00 01 11
					/*GIP Setting - APO high*/
					39 01 00 00 64 00 1B E5 0B 0A 1C 00 02 04 06 08 0F 1B 02 1A 1A 0B 0A 1C 01 03 05 07 09 10 1B 03 1A 1A
					/*Power Sequence Option Configuration*/
					39 01 00 00 00 00 06 C9 05 5D 03 04 00
					/*GIP Setting*/
					39 01 00 00 00 00 1B E5 0B 0A 0C 00 02 04 06 08 0F 1B 02 1A 1A 0B 0A 0C 01 03 05 07 09 10 1B 03 1A 1A
					/*Black Frame Setting*/
					39 01 00 00 00 00 03 BD 01 05
					05 01 00 00 05 00 01 29
				];

				qcom,mdss-dsi-off-command = [
					/* Display Off */
					05 01 00 00 00 00 01 28
					/* Sleep In + min 120ms */
					05 01 00 00 80 00 01 10
				];

				qcom,mdss-dsi-on-command-state = "dsi_lp_mode";
				qcom,mdss-dsi-on-command-with-apo-state = "dsi_lp_mode";
				qcom,mdss-dsi-off-command-state = "dsi_hs_mode";

				qcom,compression-mode = "dsc";
				qcom,mdss-dsc-version = <0x11>;
				qcom,mdss-dsc-scr-version = <0x1>;
				qcom,lm-split = <0 0>;
				qcom,mdss-dsc-encoders = <2>;
				qcom,mdss-dsc-slice-height = <60>;
				qcom,mdss-dsc-slice-width = <720>;
				qcom,mdss-dsc-slice-per-pkt = <2>;
				qcom,mdss-dsc-bit-per-component = <10>;
				qcom,mdss-dsc-bit-per-pixel = <8>;
				qcom,mdss-dsc-block-prediction-enable;
				qcom,mdss-dsi-pps-command-state = "dsi_hs_mode";
			};
		};
	};
};

&pmi8998_wled {
	status = "okay";
	qcom,fs-curr-ua = <20000>;
	qcom,led-strings-list = [00 01 02 03];
	/delete-property/ interrupt-names;
};
